# RockChip_RK3588 register map
Vendor: RockChip Electronics Co., Ltd.; Series: RK3588; File version: 0.1
Registers are 32-bit, read-write, no defined reset value unless marked. A register's access mark holds for its fields unless they carry their own. Offsets are from the block's base; [hi:lo] are bit positions; {n}, {i} and the like mark numbered series; 'fields as' and 'values as' point back to an identical list.

## CRU (part 2 of 6)
Base 0xFD7C0000
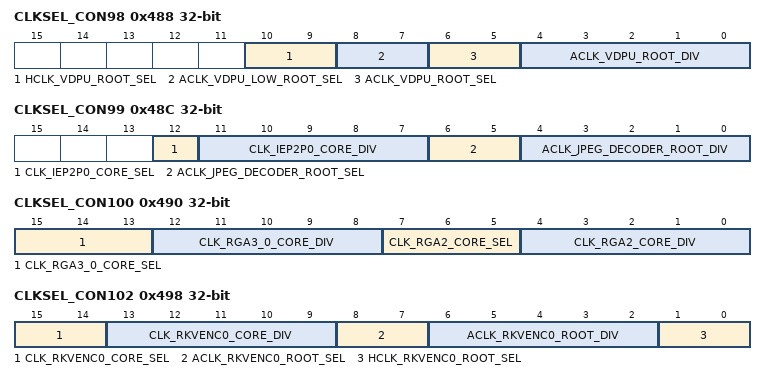
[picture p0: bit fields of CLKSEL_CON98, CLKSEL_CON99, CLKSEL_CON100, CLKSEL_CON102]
0x488 CLKSEL_CON98 — Internal clock select and division register 98
  [10:9] HCLK_VDPU_ROOT_SEL — hclk_vdpu_root clock mux.
    0=CLK_MATRIX_200M_SRC; 1=CLK_MATRIX_100M_SRC; 2=CLK_MATRIX_50M_SRC; 3=XIN_OSC0_FUNC
  [8:7] ACLK_VDPU_LOW_ROOT_SEL — aclk_vdpu_low_root clock mux.
    0=CLK_MATRIX_400M_SRC; 1=CLK_MATRIX_200M_SRC; 2=CLK_MATRIX_100M_SRC; 3=XIN_OSC0_FUNC
  [6:5] ACLK_VDPU_ROOT_SEL — aclk_vdpu_root clock mux.
    0=CLK_GPLL_MUX; 1=CLK_CPLL_MUX; 2=CLK_AUPLL_MUX
  [4:0] ACLK_VDPU_ROOT_DIV — Divide aclk_vdpu_root by (div_con + 1).
0x48C CLKSEL_CON99 — Internal clock select and division register 99
  [12] CLK_IEP2P0_CORE_SEL — clk_iep2p0_core clock mux.
    0=CLK_GPLL_MUX; 1=CLK_CPLL_MUX
  [11:7] CLK_IEP2P0_CORE_DIV — Divide clk_iep2p0_core by (div_con + 1).
  [6:5] ACLK_JPEG_DECODER_ROOT_SEL — aclk_jpeg_decoder_root clock mux.
    0=CLK_GPLL_MUX; 1=CLK_CPLL_MUX; 2=CLK_AUPLL_MUX; 3=CLK_SPLL_MUX
  [4:0] ACLK_JPEG_DECODER_ROOT_DIV — Divide aclk_jpeg_decoder_root by (div_con + 1).
0x490 CLKSEL_CON100 — Internal clock select and division register 100
  [15:13] CLK_RGA3_0_CORE_SEL — clk_rga3_0_core clock mux.
    0=CLK_GPLL_MUX; 1=CLK_CPLL_MUX; 2=CLK_NPLL_MUX; 3=CLK_AUPLL_MUX; 4=CLK_SPLL_MUX
  [12:8] CLK_RGA3_0_CORE_DIV — Divide clk_rga3_0_core by (div_con + 1).
  [7:5] CLK_RGA2_CORE_SEL — clk_rga2_core clock mux.
    values as CLK_RGA3_0_CORE_SEL
  [4:0] CLK_RGA2_CORE_DIV — Divide clk_rga2_core by (div_con + 1).
0x498 CLKSEL_CON102 — Internal clock select and division register 102
  [15:14] CLK_RKVENC0_CORE_SEL — clk_rkvenc0_core clock mux.
    0=CLK_GPLL_MUX; 1=CLK_CPLL_MUX; 2=CLK_AUPLL_MUX; 3=CLK_NPLL_MUX
  [13:9] CLK_RKVENC0_CORE_DIV — Divide clk_rkvenc0_core by (div_con + 1).
  [8:7] ACLK_RKVENC0_ROOT_SEL — aclk_rkvenc0_root clock mux.
    0=CLK_GPLL_MUX; 1=CLK_CPLL_MUX; 2=CLK_NPLL_MUX
  [6:2] ACLK_RKVENC0_ROOT_DIV — Divide aclk_rkvenc0_root by (div_con + 1).
  [1:0] HCLK_RKVENC0_ROOT_SEL — hclk_rkvenc0_root clock mux.
    values as CLKSEL_CON98.HCLK_VDPU_ROOT_SEL
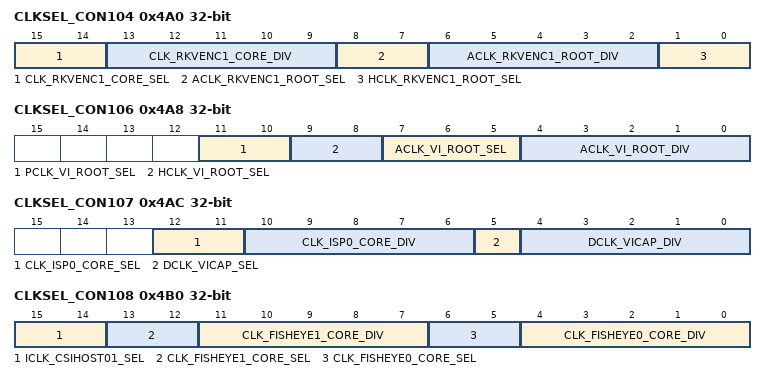
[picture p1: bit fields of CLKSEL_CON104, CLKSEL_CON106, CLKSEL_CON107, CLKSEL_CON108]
0x4A0 CLKSEL_CON104 — Internal clock select and division register 104
  [15:14] CLK_RKVENC1_CORE_SEL — clk_rkvenc1_core clock mux.
    values as CLKSEL_CON102.CLK_RKVENC0_CORE_SEL
  [13:9] CLK_RKVENC1_CORE_DIV — Divide clk_rkvenc1_core by (div_con + 1).
  [8:7] ACLK_RKVENC1_ROOT_SEL — aclk_rkvenc1_root clock mux.
    0=CLK_GPLL_MUX; 1=CLK_CPLL_MUX; 2=CLK_NPLL_MUX
  [6:2] ACLK_RKVENC1_ROOT_DIV — Divide aclk_rkvenc1_root by (div_con + 1).
  [1:0] HCLK_RKVENC1_ROOT_SEL — hclk_rkvenc1_root clock mux.
    values as CLKSEL_CON98.HCLK_VDPU_ROOT_SEL
0x4A8 CLKSEL_CON106 — Internal clock select and division register 106
  [11:10] PCLK_VI_ROOT_SEL — pclk_vi_root clock mux.
    0=CLK_MATRIX_100M_SRC; 1=CLK_MATRIX_50M_SRC; 2=XIN_OSC0_FUNC
  [9:8] HCLK_VI_ROOT_SEL — hclk_vi_root clock mux.
    values as CLKSEL_CON98.HCLK_VDPU_ROOT_SEL
  [7:5] ACLK_VI_ROOT_SEL — aclk_vi_root clock mux.
    values as CLKSEL_CON100.CLK_RGA3_0_CORE_SEL
  [4:0] ACLK_VI_ROOT_DIV — Divide aclk_vi_root by (div_con + 1).
0x4AC CLKSEL_CON107 — Internal clock select and division register 107
  [12:11] CLK_ISP0_CORE_SEL — clk_isp0_core clock mux.
    values as CLKSEL_CON99.ACLK_JPEG_DECODER_ROOT_SEL
  [10:6] CLK_ISP0_CORE_DIV — Divide clk_isp0_core by (div_con + 1).
  [5] DCLK_VICAP_SEL — dclk_vicap clock mux.
    0=CLK_GPLL_MUX; 1=CLK_CPLL_MUX
  [4:0] DCLK_VICAP_DIV — Divide dclk_vicap by (div_con + 1).
0x4B0 CLKSEL_CON108 — Internal clock select and division register 108
  [15:14] ICLK_CSIHOST01_SEL — iclk_csihost01 clock mux.
    values as CLKSEL_CON98.ACLK_VDPU_LOW_ROOT_SEL
  [13:12] CLK_FISHEYE1_CORE_SEL — clk_fisheye1_core clock mux.
    values as CLKSEL_CON99.ACLK_JPEG_DECODER_ROOT_SEL
  [11:7] CLK_FISHEYE1_CORE_DIV — Divide clk_fisheye1_core by (div_con + 1).
  [6:5] CLK_FISHEYE0_CORE_SEL — clk_fisheye0_core clock mux.
    values as CLKSEL_CON99.ACLK_JPEG_DECODER_ROOT_SEL
  [4:0] CLK_FISHEYE0_CORE_DIV — Divide clk_fisheye0_core by (div_con + 1).
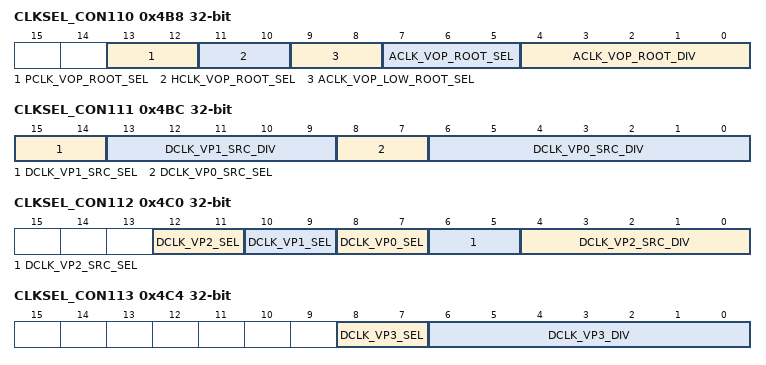
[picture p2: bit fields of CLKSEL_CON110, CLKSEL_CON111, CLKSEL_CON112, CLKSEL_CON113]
0x4B8 CLKSEL_CON110 — Internal clock select and division register 110
  [13:12] PCLK_VOP_ROOT_SEL — pclk_vop_root clock mux.
    0=CLK_MATRIX_100M_SRC; 1=CLK_MATRIX_50M_SRC; 2=XIN_OSC0_FUNC
  [11:10] HCLK_VOP_ROOT_SEL — hclk_vop_root clock mux.
    values as CLKSEL_CON98.HCLK_VDPU_ROOT_SEL
  [9:8] ACLK_VOP_LOW_ROOT_SEL — aclk_vop_low_root clock mux.
    values as CLKSEL_CON98.ACLK_VDPU_LOW_ROOT_SEL
  [7:5] ACLK_VOP_ROOT_SEL — aclk_vop_root clock mux.
    0=CLK_GPLL_MUX; 1=CLK_CPLL_MUX; 2=CLK_AUPLL_MUX; 3=CLK_NPLL_MUX; 4=CLK_SPLL_MUX
  [4:0] ACLK_VOP_ROOT_DIV — Divide aclk_vop_root by (div_con + 1).
0x4BC CLKSEL_CON111 — Internal clock select and division register 111
  [15:14] DCLK_VP1_SRC_SEL — dclk_vp1_src clock mux.
    0=CLK_GPLL_MUX; 1=CLK_CPLL_MUX; 2=CLK_V0PLL_MUX; 3=CLK_AUPLL_MUX
  [13:9] DCLK_VP1_SRC_DIV — Divide dclk_vp1_src by (div_con + 1).
  [8:7] DCLK_VP0_SRC_SEL — dclk_vp0_src clock mux.
    values as DCLK_VP1_SRC_SEL
  [6:0] DCLK_VP0_SRC_DIV — Divide dclk_vp0_src by (div_con + 1).
0x4C0 CLKSEL_CON112 — Internal clock select and division register 112
  [12:11] DCLK_VP2_SEL — dclk_vp2 clock mux.
    0=DCLK_VP2_SRC; 1=CLK_HDMIPHY_PIXEL0_O; 2=CLK_HDMIPHY_PIXEL1_O
  [10:9] DCLK_VP1_SEL — dclk_vp1 clock mux.
    0=DCLK_VP1_SRC; 1=CLK_HDMIPHY_PIXEL0_O; 2=CLK_HDMIPHY_PIXEL1_O
  [8:7] DCLK_VP0_SEL — dclk_vp0 clock mux.
    0=DCLK_VP0_SRC; 1=CLK_HDMIPHY_PIXEL0_O; 2=CLK_HDMIPHY_PIXEL1_O
  [6:5] DCLK_VP2_SRC_SEL — dclk_vp2_src clock mux.
    values as CLKSEL_CON111.DCLK_VP1_SRC_SEL
  [4:0] DCLK_VP2_SRC_DIV — Divide dclk_vop2_src by (div_con + 1).
0x4C4 CLKSEL_CON113 — Internal clock select and division register 113
  [8:7] DCLK_VP3_SEL — dclk_vp3 clock mux.
    values as CLKSEL_CON111.DCLK_VP1_SRC_SEL
  [6:0] DCLK_VP3_DIV — Divide dclk_vp3 by (div_con + 1).
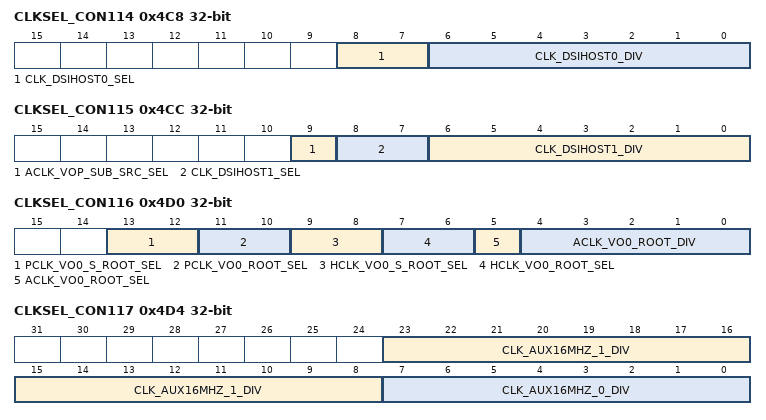
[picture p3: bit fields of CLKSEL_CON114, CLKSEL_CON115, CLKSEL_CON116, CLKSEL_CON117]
0x4C8 CLKSEL_CON114 — Internal clock select and division register 114
  [8:7] CLK_DSIHOST0_SEL — clk_dsihost0 clock mux.
    0=CLK_GPLL_MUX; 1=CLK_CPLL_MUX; 2=CLK_V0PLL_MUX; 3=CLK_SPLL_MUX
  [6:0] CLK_DSIHOST0_DIV — Divide clk_dsihost0 by (div_con + 1).
0x4CC CLKSEL_CON115 — Internal clock select and division register 115
  [9] ACLK_VOP_SUB_SRC_SEL — aclk_vop_sub_src clock mux.
    0=ACLK_VOP_ROOT; 1=ACLK_VOP_DIV2_SRC
  [8:7] CLK_DSIHOST1_SEL — clk_dsihost1 clock mux.
    values as CLKSEL_CON114.CLK_DSIHOST0_SEL
  [6:0] CLK_DSIHOST1_DIV — Divide clk_dsihost1 by (div_con + 1).
0x4D0 CLKSEL_CON116 — Internal clock select and division register 116
  [13:12] PCLK_VO0_S_ROOT_SEL — pclk_vo0_s_root clock mux.
    0=CLK_MATRIX_100M_SRC; 1=CLK_MATRIX_50M_SRC; 2=XIN_OSC0_FUNC
  [11:10] PCLK_VO0_ROOT_SEL — pclk_vo0_root clock mux.
    0=CLK_MATRIX_100M_SRC; 1=CLK_MATRIX_50M_SRC; 2=XIN_OSC0_FUNC
  [9:8] HCLK_VO0_S_ROOT_SEL — hclk_vo0_s_root clock mux.
    values as CLKSEL_CON98.HCLK_VDPU_ROOT_SEL
  [7:6] HCLK_VO0_ROOT_SEL — hclk_vo0_root clock mux.
    values as CLKSEL_CON98.HCLK_VDPU_ROOT_SEL
  [5] ACLK_VO0_ROOT_SEL — aclk_vo0_root clock mux.
    0=CLK_GPLL_MUX; 1=CLK_CPLL_MUX
  [4:0] ACLK_VO0_ROOT_DIV — Divide aclk_vo0_root by (div_con + 1).
0x4D4 CLKSEL_CON117 — Internal clock select and division register 117
  [23:8] CLK_AUX16MHZ_1_DIV — Divide clk_aux16mhz_1 by (div_con + 1).
  [7:0] CLK_AUX16MHZ_0_DIV — Divide clk_aux16mhz_0 by (div_con + 1).
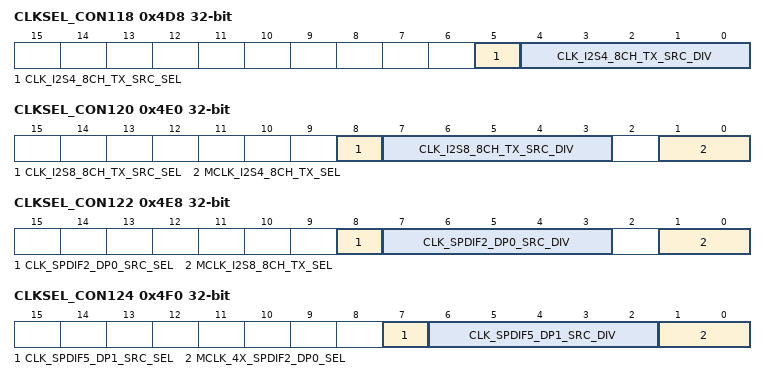
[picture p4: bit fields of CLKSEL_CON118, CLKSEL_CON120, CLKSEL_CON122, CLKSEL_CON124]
0x4D8 CLKSEL_CON118 — Internal clock select and division register 118
  [5] CLK_I2S4_8CH_TX_SRC_SEL — clk_i2s4_8ch_tx_src clock mux.
    0=CLK_GPLL_MUX; 1=CLK_AUPLL_MUX
  [4:0] CLK_I2S4_8CH_TX_SRC_DIV — Divide clk_i2s4_8ch_tx_src by (div_con + 1).
0x4DC CLKSEL_CON119 — Internal clock select and division register 119
  [31:0] CLK_I2S4_8CH_TX_FRAC_DIV — clk_i2s4_8ch_tx_frac fraction division register. High 16-bit for numerator Low 16-bit for denominator
0x4E0 CLKSEL_CON120 — Internal clock select and division register 120
  [8] CLK_I2S8_8CH_TX_SRC_SEL — clk_i2s8_8ch_tx_src clock mux.
    0=CLK_GPLL_MUX; 1=CLK_AUPLL_MUX
  [7:3] CLK_I2S8_8CH_TX_SRC_DIV — Divide clk_i2s8_8ch_tx_src by (div_con + 1).
  [1:0] MCLK_I2S4_8CH_TX_SEL — mclk_i2s4_8ch_tx clock mux.
    0=CLK_I2S4_8CH_TX_SRC; 1=CLK_I2S4_8CH_TX_FRAC; 2=I2S4_MCLKIN; 3=XIN_OSC0_HALF
0x4E4 CLKSEL_CON121 — Internal clock select and division register 121
  [31:0] CLK_I2S8_8CH_TX_FRAC_DIV — clk_i2s8_8ch_tx_frac fraction division register. High 16-bit for numerator Low 16-bit for denominator
0x4E8 CLKSEL_CON122 — Internal clock select and division register 122
  [8] CLK_SPDIF2_DP0_SRC_SEL — clk_spdif2_dp0_src clock mux.
    0=CLK_GPLL_MUX; 1=CLK_AUPLL_MUX
  [7:3] CLK_SPDIF2_DP0_SRC_DIV — Divide clk_spdif2_dp0_src by (div_con + 1).
  [1:0] MCLK_I2S8_8CH_TX_SEL — mclk_i2s8_8ch_tx clock mux.
    0=CLK_I2S8_8CH_TX_SRC; 1=CLK_I2S8_8CH_TX_FRAC; 2=I2S8_MCLKIN; 3=XIN_OSC0_HALF
0x4EC CLKSEL_CON123 — Internal clock select and division register 123
  [31:0] CLK_SPDIF2_DP0_FRAC_DIV — clk_spdif2_dp0_frac fraction division register. High 16-bit for numerator Low 16-bit for denominator
0x4F0 CLKSEL_CON124 — Internal clock select and division register 124
  [7] CLK_SPDIF5_DP1_SRC_SEL — clk_spdif5_dp1_src clock mux.
    0=CLK_GPLL_MUX; 1=CLK_AUPLL_MUX
  [6:2] CLK_SPDIF5_DP1_SRC_DIV — Divide clk_spdif5_dp1_src by (div_con + 1).
  [1:0] MCLK_4X_SPDIF2_DP0_SEL — mclk_4x_spdif2_dp0 clock mux.
    0=CLK_SPDIF2_DP0_SRC; 1=CLK_SPDIF2_DP0_FRAC; 2=XIN_OSC0_HALF
0x4F4 CLKSEL_CON125 — Internal clock select and division register 125
  [31:0] CLK_SPDIF5_DP1_FRAC_DIV — clk_spdif5_dp1_frac fraction division register. High 16-bit for numerator Low 16-bit for denominator
0x4F8 CLKSEL_CON126 — Internal clock select and division register 126
  [1:0] MCLK_4X_SPDIF5_DP1_SEL — mclk_4x_spdif5_dp1 clock mux.
    0=CLK_SPDIF5_DP1_SRC; 1=CLK_SPDIF5_DP1_FRAC; 2=XIN_OSC0_HALF
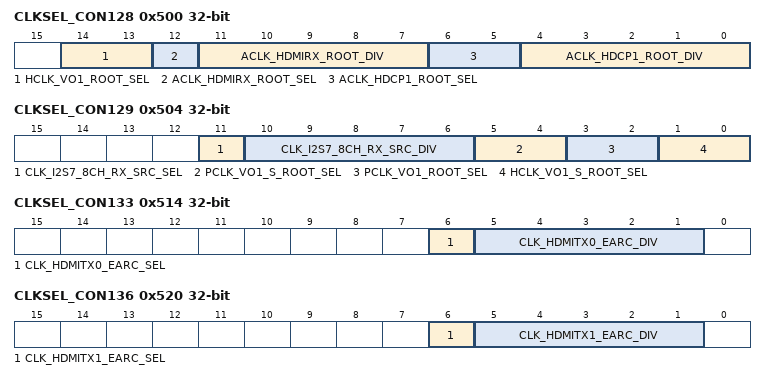
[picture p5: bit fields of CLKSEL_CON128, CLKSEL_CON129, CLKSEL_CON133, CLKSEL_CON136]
0x500 CLKSEL_CON128 — Internal clock select and division register 128
  [14:13] HCLK_VO1_ROOT_SEL — hclk_vo1_root clock mux.
    values as CLKSEL_CON98.HCLK_VDPU_ROOT_SEL
  [12] ACLK_HDMIRX_ROOT_SEL — aclk_hdmirx_root clock mux.
    0=CLK_GPLL_MUX; 1=CLK_CPLL_MUX
  [11:7] ACLK_HDMIRX_ROOT_DIV — Divide aclk_hdmirx_root by (div_con + 1).
  [6:5] ACLK_HDCP1_ROOT_SEL — aclk_hdcp1_root clock mux.
    0=CLK_GPLL_MUX; 1=CLK_CPLL_MUX; 2=CLK_HDMITRX_REFSRC
  [4:0] ACLK_HDCP1_ROOT_DIV — Divide aclk_hdcp1_root by (div_con + 1).
0x504 CLKSEL_CON129 — Internal clock select and division register 129
  [11] CLK_I2S7_8CH_RX_SRC_SEL — clk_i2s7_8ch_rx_src clock mux.
    0=CLK_GPLL_MUX; 1=CLK_AUPLL_MUX
  [10:6] CLK_I2S7_8CH_RX_SRC_DIV — Divide clk_i2s7_8ch_rx_src by (div_con + 1).
  [5:4] PCLK_VO1_S_ROOT_SEL — pclk_vo1_s_root clock mux.
    0=CLK_MATRIX_100M_SRC; 1=CLK_MATRIX_50M_SRC; 2=XIN_OSC0_FUNC
  [3:2] PCLK_VO1_ROOT_SEL — pclk_vo1_root clock mux.
    0=CLK_MATRIX_150M_SRC; 1=CLK_MATRIX_100M_SRC; 2=XIN_OSC0_FUNC
  [1:0] HCLK_VO1_S_ROOT_SEL — hclk_vo1_s_root clock mux.
    values as CLKSEL_CON98.HCLK_VDPU_ROOT_SEL
0x508 CLKSEL_CON130 — Internal clock select and division register 130
  [31:0] CLK_I2S7_8CH_RX_FRAC_DIV — clk_i2s7_8ch_rx_frac fraction division register. High 16-bit for numerator Low 16-bit for denominator
0x50C CLKSEL_CON131 — Internal clock select and division register 131
  [1:0] MCLK_I2S7_8CH_RX_SEL — mclk_i2s7_8ch_rx clock mux.
    0=CLK_I2S7_8CH_RX_SRC; 1=CLK_I2S7_8CH_RX_FRAC; 2=I2S7_MCLKIN; 3=XIN_OSC0_HALF
0x514 CLKSEL_CON133 — Internal clock select and division register 133
  [6] CLK_HDMITX0_EARC_SEL — clk_hdmitx0_earc clock mux.
    0=CLK_GPLL_MUX; 1=CLK_CPLL_MUX
  [5:1] CLK_HDMITX0_EARC_DIV — Divide clk_hdmitx0_earc by (div_con + 1).
0x520 CLKSEL_CON136 — Internal clock select and division register 136
  [6] CLK_HDMITX1_EARC_SEL — clk_hdmitx1_earc clock mux.
    0=CLK_GPLL_MUX; 1=CLK_CPLL_MUX
  [5:1] CLK_HDMITX1_EARC_DIV — Divide clk_hdmitx1_earc by (div_con + 1).
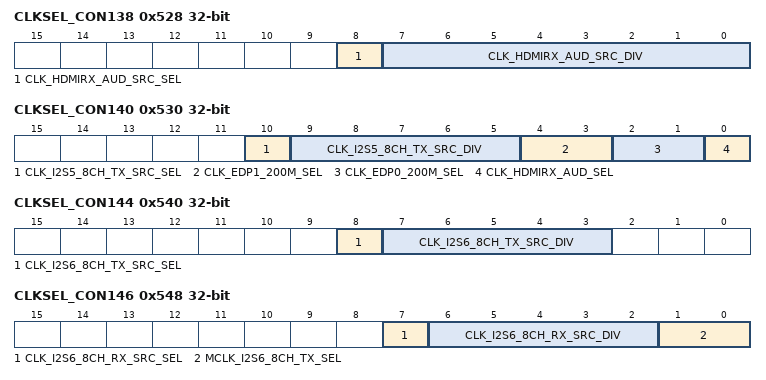
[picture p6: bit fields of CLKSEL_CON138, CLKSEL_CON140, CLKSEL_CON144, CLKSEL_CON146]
0x528 CLKSEL_CON138 — Internal clock select and division register 138
  [8] CLK_HDMIRX_AUD_SRC_SEL — clk_hdmirx_aud_src clock mux.
    0=CLK_GPLL_MUX; 1=CLK_AUPLL_MUX
  [7:0] CLK_HDMIRX_AUD_SRC_DIV — Divide clk_hdmirx_aud_src by (div_con + 1).
0x52C CLKSEL_CON139 — Internal clock select and division register 139
  [31:0] CLK_HDMIRX_AUD_FRAC_DIV — clk_hdmirx_aud_frac fraction division register. High 16-bit for numerator Low 16-bit for denominator
0x530 CLKSEL_CON140 — Internal clock select and division register 140
  [10] CLK_I2S5_8CH_TX_SRC_SEL — clk_i2s5_8ch_tx_src clock mux.
    0=CLK_GPLL_MUX; 1=CLK_AUPLL_MUX
  [9:5] CLK_I2S5_8CH_TX_SRC_DIV — Divide clk_i2s5_8ch_tx_src by (div_con + 1).
  [4:3] CLK_EDP1_200M_SEL — clk_edp1_200m clock mux.
    values as CLKSEL_CON98.HCLK_VDPU_ROOT_SEL
  [2:1] CLK_EDP0_200M_SEL — clk_edp0_200m clock mux.
    values as CLKSEL_CON98.HCLK_VDPU_ROOT_SEL
  [0] CLK_HDMIRX_AUD_SEL — clk_hdmirx_aud clock mux.
    0=CLK_HDMIRX_AUD_SRC; 1=CLK_HDMIRX_AUD_FRAC
0x534 CLKSEL_CON141 — Internal clock select and division register 141
  [31:0] CLK_I2S5_8CH_TX_FRAC_DIV — clk_i2s5_8ch_tx_frac fraction division register. High 16-bit for numerator Low 16-bit for denominator
0x538 CLKSEL_CON142 — Internal clock select and division register 142
  [1:0] MCLK_I2S5_8CH_TX_SEL — mclk_i2s5_8ch_tx clock mux.
    0=CLK_I2S5_8CH_TX_SRC; 1=CLK_I2S5_8CH_TX_FRAC; 2=I2S5_MCLKIN; 3=XIN_OSC0_HALF
0x540 CLKSEL_CON144 — Internal clock select and division register 144
  [8] CLK_I2S6_8CH_TX_SRC_SEL — clk_i2s6_8ch_tx_src clock mux.
    0=CLK_GPLL_MUX; 1=CLK_AUPLL_MUX
  [7:3] CLK_I2S6_8CH_TX_SRC_DIV — Divide clk_i2s6_8ch_tx_src by (div_con + 1).
0x544 CLKSEL_CON145 — Internal clock select and division register 145
  [31:0] CLK_I2S6_8CH_TX_FRAC_DIV — clk_i2s6_8ch_tx_frac fraction division register. High 16-bit for numerator Low 16-bit for denominator
0x548 CLKSEL_CON146 — Internal clock select and division register 146
  [7] CLK_I2S6_8CH_RX_SRC_SEL — clk_i2s6_8ch_rx_src clock mux.
    0=CLK_GPLL_MUX; 1=CLK_AUPLL_MUX
  [6:2] CLK_I2S6_8CH_RX_SRC_DIV — Divide clk_i2s6_8ch_rx_src by (div_con + 1).
  [1:0] MCLK_I2S6_8CH_TX_SEL — mclk_i2s6_8ch_tx clock mux.
    0=CLK_I2S6_8CH_TX_SRC; 1=CLK_I2S6_8CH_TX_FRAC; 2=I2S6_MCLKIN; 3=XIN_OSC0_HALF
0x54C CLKSEL_CON147 — Internal clock select and division register 147
  [31:0] CLK_I2S6_8CH_RX_FRAC_DIV — clk_i2s6_8ch_rx_frac fraction division register. High 16-bit for numerator Low 16-bit for denominator
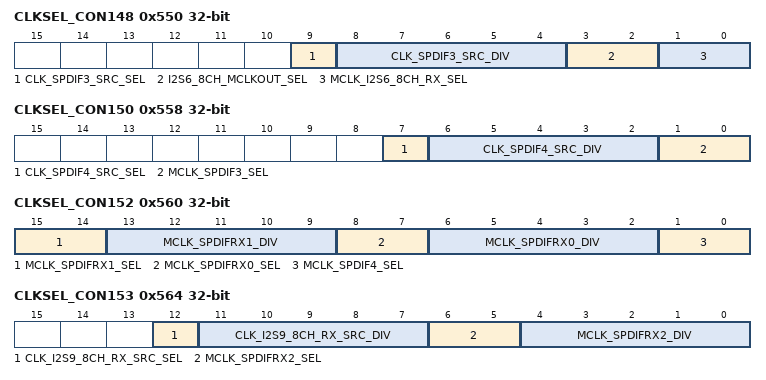
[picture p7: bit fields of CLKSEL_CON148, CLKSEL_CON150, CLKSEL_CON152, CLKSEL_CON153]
0x550 CLKSEL_CON148 — Internal clock select and division register 148
  [9] CLK_SPDIF3_SRC_SEL — clk_spdif3_src clock mux.
    0=CLK_GPLL_MUX; 1=CLK_AUPLL_MUX
  [8:4] CLK_SPDIF3_SRC_DIV — Divide clk_spdif3_src by (div_con + 1).
  [3:2] I2S6_8CH_MCLKOUT_SEL — i2s6_8ch_mclkout clock mux.
    0=MCLK_I2S6_8CH_TX; 1=MCLK_I2S6_8CH_RX; 2=XIN_OSC0_HALF
  [1:0] MCLK_I2S6_8CH_RX_SEL — mclk_i2s6_8ch_rx clock mux.
    0=CLK_I2S6_8CH_RX_SRC; 1=CLK_I2S6_8CH_RX_FRAC; 2=I2S6_MCLKIN; 3=XIN_OSC0_HALF
0x554 CLKSEL_CON149 — Internal clock select and division register 149
  [31:0] CLK_SPDIF3_FRAC_DIV — clk_spdif3_frac fraction division register. High 16-bit for numerator Low 16-bit for denominator
0x558 CLKSEL_CON150 — Internal clock select and division register 150
  [7] CLK_SPDIF4_SRC_SEL — clk_spdif4_src clock mux.
    0=CLK_GPLL_MUX; 1=CLK_AUPLL_MUX
  [6:2] CLK_SPDIF4_SRC_DIV — Divide clk_spdif4_src by (div_con + 1).
  [1:0] MCLK_SPDIF3_SEL — mclk_spdif3 clock mux.
    0=CLK_SPDIF3_SRC; 1=CLK_SPDIF3_FRAC; 2=XIN_OSC0_HALF
0x55C CLKSEL_CON151 — Internal clock select and division register 151
  [31:0] CLK_SPDIF4_FRAC_DIV — clk_spdif4_frac fraction division register. High 16-bit for numerator Low 16-bit for denominator
0x560 CLKSEL_CON152 — Internal clock select and division register 152
  [15:14] MCLK_SPDIFRX1_SEL — mclk_spdifrx1 clock mux.
    0=CLK_GPLL_MUX; 1=CLK_CPLL_MUX; 2=CLK_AUPLL_MUX
  [13:9] MCLK_SPDIFRX1_DIV — Divide mclk_spdifrx1 by (div_con + 1).
  [8:7] MCLK_SPDIFRX0_SEL — mclk_spdifrx0 clock mux.
    0=CLK_GPLL_MUX; 1=CLK_CPLL_MUX; 2=CLK_AUPLL_MUX
  [6:2] MCLK_SPDIFRX0_DIV — Divide mclk_spdifrx0 by (div_con + 1).
  [1:0] MCLK_SPDIF4_SEL — mclk_spdif4 clock mux.
    0=CLK_SPDIF4_SRC; 1=CLK_SPDIF4_FRAC; 2=XIN_OSC0_HALF
0x564 CLKSEL_CON153 — Internal clock select and division register 153
  [12] CLK_I2S9_8CH_RX_SRC_SEL — clk_i2s9_8ch_rx_src clock mux.
    0=CLK_GPLL_MUX; 1=CLK_AUPLL_MUX
  [11:7] CLK_I2S9_8CH_RX_SRC_DIV — Divide clk_i2s9_8ch_rx_src by (div_con + 1).
  [6:5] MCLK_SPDIFRX2_SEL — mclk_spdifrx2 clock mux.
    0=CLK_GPLL_MUX; 1=CLK_CPLL_MUX; 2=CLK_AUPLL_MUX
  [4:0] MCLK_SPDIFRX2_DIV — Divide mclk_spdifrx2 by (div_con + 1).
0x568 CLKSEL_CON154 — Internal clock select and division register 154
  [31:0] CLK_I2S9_8CH_RX_FRAC_DIV — clk_i2s9_8ch_rx_frac fraction division register. High 16-bit for numerator Low 16-bit for denominator
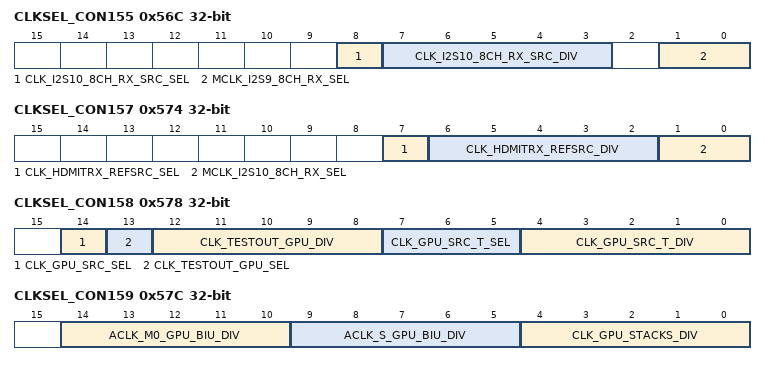
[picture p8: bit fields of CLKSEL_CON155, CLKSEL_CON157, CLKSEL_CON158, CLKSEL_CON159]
0x56C CLKSEL_CON155 — Internal clock select and division register 155
  [8] CLK_I2S10_8CH_RX_SRC_SEL — clk_i2s10_8ch_rx_src clock mux.
    0=CLK_GPLL_MUX; 1=CLK_AUPLL_MUX
  [7:3] CLK_I2S10_8CH_RX_SRC_DIV — Divide clk_i2s10_8ch_rx_src by (div_con + 1).
  [1:0] MCLK_I2S9_8CH_RX_SEL — mclk_i2s9_8ch_rx clock mux.
    0=CLK_I2S9_8CH_RX_SRC; 1=CLK_I2S9_8CH_RX_FRAC; 2=I2S9_MCLKIN; 3=XIN_OSC0_HALF
0x570 CLKSEL_CON156 — Internal clock select and division register 156
  [31:0] CLK_I2S10_8CH_RX_FRAC_DIV — clk_i2s10_8ch_rx_frac fraction division register. High 16-bit for numerator Low 16-bit for denominator
0x574 CLKSEL_CON157 — Internal clock select and division register 157
  [7] CLK_HDMITRX_REFSRC_SEL — clk_hdmitrx_refsrc clock mux.
    0=CLK_GPLL_MUX; 1=CLK_CPLL_MUX
  [6:2] CLK_HDMITRX_REFSRC_DIV — NP5 division register. Divide clk_hdmitrx_refsrc by ((2 * div_con + 3) / 2).
  [1:0] MCLK_I2S10_8CH_RX_SEL — mclk_i2s10_8ch_rx clock mux.
    0=CLK_I2S10_8CH_RX_SRC; 1=CLK_I2S10_8CH_RX_FRAC; 2=I2S10_MCLKIN; 3=XIN_OSC0_HALF
0x578 CLKSEL_CON158 — Internal clock select and division register 158
  [14] CLK_GPU_SRC_SEL — clk_gpu_src clock mux.
    0=CLK_GPU_SRC_T; 1=CLK_GPU_PVTPLL
  [13] CLK_TESTOUT_GPU_SEL — clk_testout_gpu clock mux.
    0=CLK_GPU_SRC_T; 1=CLK_GPU_PVTPLL
  [12:8] CLK_TESTOUT_GPU_DIV — Divide clk_testout_gpu by (div_con + 1).
  [7:5] CLK_GPU_SRC_T_SEL — clk_gpu_src_t clock mux.
    values as CLKSEL_CON110.ACLK_VOP_ROOT_SEL
  [4:0] CLK_GPU_SRC_T_DIV — Divide clk_gpu_src_t by (div_con + 1).
0x57C CLKSEL_CON159 — Internal clock select and division register 159
  [14:10] ACLK_M0_GPU_BIU_DIV — Divide aclk_m0_gpu_biu by (div_con + 1).
  [9:5] ACLK_S_GPU_BIU_DIV — Divide aclk_s_gpu_biu by (div_con + 1).
  [4:0] CLK_GPU_STACKS_DIV — Divide clk_gpu_stacks by (div_con + 1).
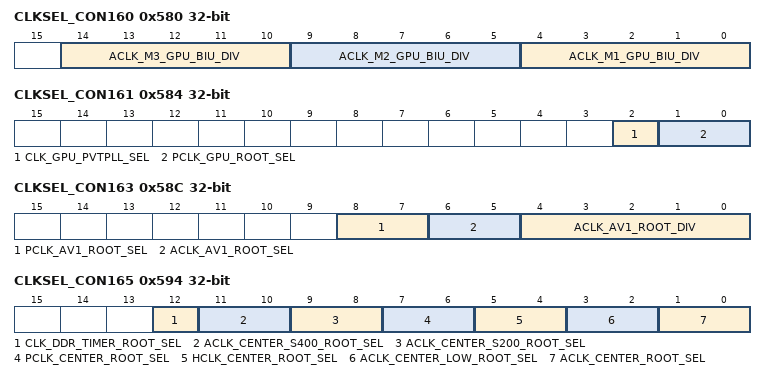
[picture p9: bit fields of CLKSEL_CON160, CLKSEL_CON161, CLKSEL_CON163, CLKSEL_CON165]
0x580 CLKSEL_CON160 — Internal clock select and division register 160
  [14:10] ACLK_M3_GPU_BIU_DIV — Divide aclk_m3_gpu_biu by (div_con + 1).
  [9:5] ACLK_M2_GPU_BIU_DIV — Divide aclk_m2_gpu_biu by (div_con + 1).
  [4:0] ACLK_M1_GPU_BIU_DIV — Divide aclk_m1_gpu_biu by (div_con + 1).
0x584 CLKSEL_CON161 — Internal clock select and division register 161
  [2] CLK_GPU_PVTPLL_SEL — clk_gpu_pvtpll clock mux.
    0=CLK_GPU_SRC_T; 1=XIN_OSC0_FUNC
  [1:0] PCLK_GPU_ROOT_SEL — pclk_gpu_root clock mux.
    0=CLK_MATRIX_100M_SRC; 1=CLK_MATRIX_50M_SRC; 2=XIN_OSC0_FUNC
0x58C CLKSEL_CON163 — Internal clock select and division register 163
  [8:7] PCLK_AV1_ROOT_SEL — pclk_av1_root clock mux.
    values as CLKSEL_CON98.HCLK_VDPU_ROOT_SEL
  [6:5] ACLK_AV1_ROOT_SEL — aclk_av1_root clock mux.
    0=CLK_GPLL_MUX; 1=CLK_CPLL_MUX; 2=CLK_AUPLL_MUX
  [4:0] ACLK_AV1_ROOT_DIV — Divide aclk_av1_root by (div_con + 1).
0x594 CLKSEL_CON165 — Internal clock select and division register 165
  [12] CLK_DDR_TIMER_ROOT_SEL — clk_ddr_timer_root clock mux.
    0=XIN_OSC0_FUNC; 1=CLK_MATRIX_100M_SRC
  [11:10] ACLK_CENTER_S400_ROOT_SEL — aclk_center_s400_root clock mux.
    values as CLKSEL_CON98.ACLK_VDPU_LOW_ROOT_SEL
  [9:8] ACLK_CENTER_S200_ROOT_SEL — aclk_center_s200_root clock mux.
    values as CLKSEL_CON98.HCLK_VDPU_ROOT_SEL
  [7:6] PCLK_CENTER_ROOT_SEL — pclk_center_root clock mux.
    values as CLKSEL_CON98.HCLK_VDPU_ROOT_SEL
  [5:4] HCLK_CENTER_ROOT_SEL — hclk_center_root clock mux.
    values as CLKSEL_CON98.ACLK_VDPU_LOW_ROOT_SEL
  [3:2] ACLK_CENTER_LOW_ROOT_SEL — aclk_center_low_root clock mux.
    0=CLK_MATRIX_500M_SRC; 1=CLK_MATRIX_250M_SRC; 2=CLK_MATRIX_100M_SRC; 3=XIN_OSC0_FUNC
  [1:0] ACLK_CENTER_ROOT_SEL — aclk_center_root clock mux.
    0=CLK_MATRIX_700M_SRC; 1=CLK_MATRIX_400M_SRC; 2=CLK_MATRIX_200M_SRC; 3=XIN_OSC0_FUNC
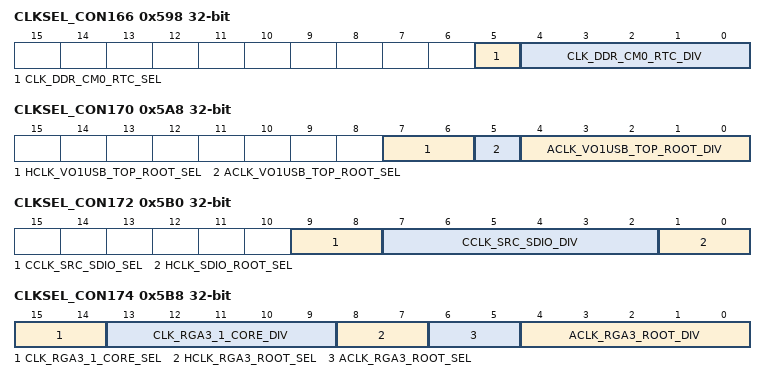
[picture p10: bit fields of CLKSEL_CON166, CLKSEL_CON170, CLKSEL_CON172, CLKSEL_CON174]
0x598 CLKSEL_CON166 — Internal clock select and division register 166
  [5] CLK_DDR_CM0_RTC_SEL — clk_ddr_cm0_rtc clock mux.
    0=XIN_OSC0_FUNC; 1=CLK_DEEPSLOW
  [4:0] CLK_DDR_CM0_RTC_DIV — Divide clk_ddr_cm0_rtc by (div_con + 1).
0x5A8 CLKSEL_CON170 — Internal clock select and division register 170
  [7:6] HCLK_VO1USB_TOP_ROOT_SEL — hclk_vo1usb_top_root clock mux.
    values as CLKSEL_CON98.HCLK_VDPU_ROOT_SEL
  [5] ACLK_VO1USB_TOP_ROOT_SEL — aclk_vo1usb_top_root clock mux.
    0=CLK_GPLL_MUX; 1=CLK_CPLL_MUX
  [4:0] ACLK_VO1USB_TOP_ROOT_DIV — Divide aclk_vo1usb_top_root by (div_con + 1).
0x5B0 CLKSEL_CON172 — Internal clock select and division register 172
  [9:8] CCLK_SRC_SDIO_SEL — cclk_src_sdio clock mux.
    0=CLK_GPLL_MUX; 1=CLK_CPLL_MUX; 2=XIN_OSC0_FUNC
  [7:2] CCLK_SRC_SDIO_DIV — DT50 division register. Divide cclk_src_sdio by (div_con + 1).
  [1:0] HCLK_SDIO_ROOT_SEL — hclk_sdio_root clock mux.
    values as CLKSEL_CON98.HCLK_VDPU_ROOT_SEL
0x5B8 CLKSEL_CON174 — Internal clock select and division register 174
  [15:14] CLK_RGA3_1_CORE_SEL — clk_rga3_1_core clock mux.
    values as CLKSEL_CON99.ACLK_JPEG_DECODER_ROOT_SEL
  [13:9] CLK_RGA3_1_CORE_DIV — Divide clk_rga3_1_core by (div_con + 1).
  [8:7] HCLK_RGA3_ROOT_SEL — hclk_rga3_root clock mux.
    values as CLKSEL_CON98.HCLK_VDPU_ROOT_SEL
  [6:5] ACLK_RGA3_ROOT_SEL — aclk_rga3_root clock mux.
    0=CLK_GPLL_MUX; 1=CLK_CPLL_MUX; 2=CLK_AUPLL_MUX
  [4:0] ACLK_RGA3_ROOT_DIV — Divide aclk_rga3_root by (div_con + 1).
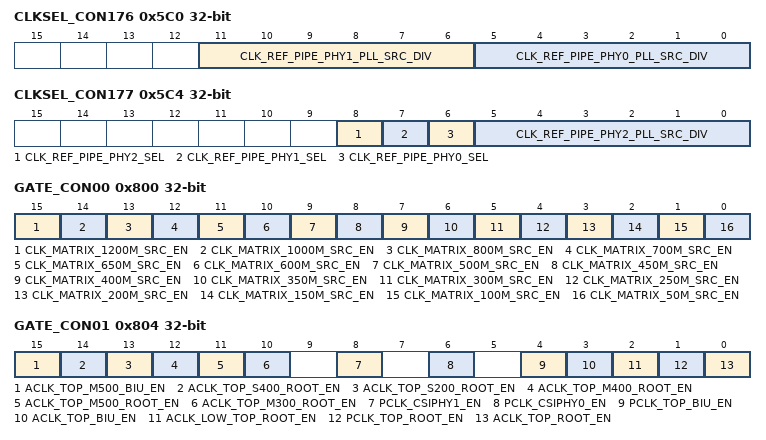
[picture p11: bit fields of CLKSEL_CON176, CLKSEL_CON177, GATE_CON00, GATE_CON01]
0x5C0 CLKSEL_CON176 — Internal clock select and division register 176
  [11:6] CLK_REF_PIPE_PHY1_PLL_SRC_DIV — Divide clk_ref_pipe_phy1_pll_src by (div_con + 1).
  [5:0] CLK_REF_PIPE_PHY0_PLL_SRC_DIV — Divide clk_ref_pipe_phy0_pll_src by (div_con + 1).
0x5C4 CLKSEL_CON177 — Internal clock select and division register 177
  [8] CLK_REF_PIPE_PHY2_SEL — clk_ref_pipe_phy2 clock mux.
    0=CLK_REF_PIPE_PHY2_OSC_SRC; 1=CLK_REF_PIPE_PHY2_PLL_SRC
  [7] CLK_REF_PIPE_PHY1_SEL — clk_ref_pipe_phy1 clock mux.
    0=CLK_REF_PIPE_PHY1_OSC_SRC; 1=CLK_REF_PIPE_PHY1_PLL_SRC
  [6] CLK_REF_PIPE_PHY0_SEL — clk_ref_pipe_phy0 clock mux.
    0=CLK_REF_PIPE_PHY0_OSC_SRC; 1=CLK_REF_PIPE_PHY0_PLL_SRC
  [5:0] CLK_REF_PIPE_PHY2_PLL_SRC_DIV — Divide clk_ref_pipe_phy2_pll_src by (div_con + 1).
0x800 GATE_CON00 — Internal clock gate and division register 0
  [all] fields
    1=DISABLE; 0=ENABLE
  [15] CLK_MATRIX_1200M_SRC_EN — clk_matrix_1200m_src clock gating control.
  [14] CLK_MATRIX_1000M_SRC_EN — clk_matrix_1000m_src clock gating control.
  [13] CLK_MATRIX_800M_SRC_EN — clk_matrix_800m_src clock gating control.
  [12] CLK_MATRIX_700M_SRC_EN — clk_matrix_700m_src clock gating control.
  [11] CLK_MATRIX_650M_SRC_EN — clk_matrix_650m_src clock gating control.
  [10] CLK_MATRIX_600M_SRC_EN — clk_matrix_600m_src clock gating control.
  [9] CLK_MATRIX_500M_SRC_EN — clk_matrix_500m_src clock gating control.
  [8] CLK_MATRIX_450M_SRC_EN — clk_matrix_450m_src clock gating control.
  [7] CLK_MATRIX_400M_SRC_EN — clk_matrix_400m_src clock gating control.
  [6] CLK_MATRIX_350M_SRC_EN — clk_matrix_350m_src clock gating control.
  [5] CLK_MATRIX_300M_SRC_EN — clk_matrix_300m_src clock gating control.
  [4] CLK_MATRIX_250M_SRC_EN — clk_matrix_250m_src clock gating control.
  [3] CLK_MATRIX_200M_SRC_EN — clk_matrix_200m_src clock gating control.
  [2] CLK_MATRIX_150M_SRC_EN — clk_matrix_150m_src clock gating control.
  [1] CLK_MATRIX_100M_SRC_EN — clk_matrix_100m_src clock gating control.
  [0] CLK_MATRIX_50M_SRC_EN — clk_matrix_50m_src clock gating control.
0x804 GATE_CON01 — Internal clock gate and division register 1
  [all] fields
    1=DISABLE; 0=ENABLE
  [15] ACLK_TOP_M500_BIU_EN — aclk_top_m500_biu clock gating control.
  [14] ACLK_TOP_S400_ROOT_EN — aclk_top_s400_root clock gating control.
  [13] ACLK_TOP_S200_ROOT_EN — aclk_top_s200_root clock gating control.
  [12] ACLK_TOP_M400_ROOT_EN — aclk_top_m400_root clock gating control.
  [11] ACLK_TOP_M500_ROOT_EN — aclk_top_m500_root clock gating control.
  [10] ACLK_TOP_M300_ROOT_EN — aclk_top_m300_root clock gating control.
  [8] PCLK_CSIPHY1_EN — pclk_csiphy1 clock gating control.
  [6] PCLK_CSIPHY0_EN — pclk_csiphy0 clock gating control.
  [4] PCLK_TOP_BIU_EN — pclk_top_biu clock gating control.
  [3] ACLK_TOP_BIU_EN — aclk_top_biu clock gating control.
  [2] ACLK_LOW_TOP_ROOT_EN — aclk_low_top_root clock gating control.
  [1] PCLK_TOP_ROOT_EN — pclk_top_root clock gating control.
  [0] ACLK_TOP_ROOT_EN — aclk_top_root clock gating control.
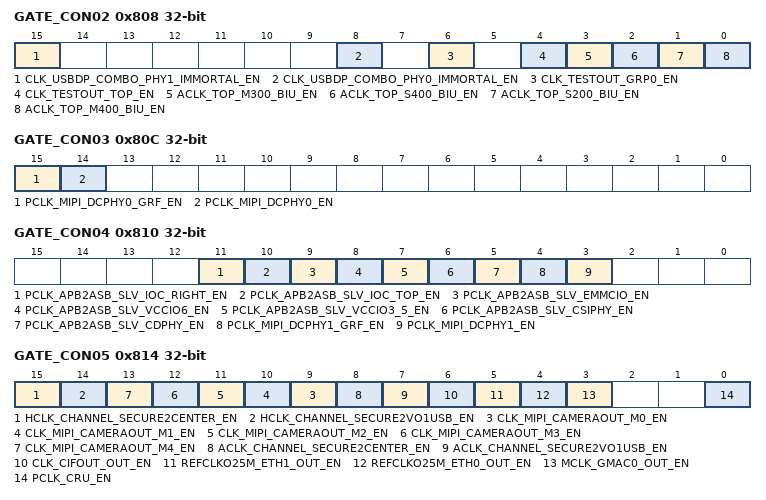
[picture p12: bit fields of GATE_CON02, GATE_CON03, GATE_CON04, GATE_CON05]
0x808 GATE_CON02 — Internal clock gate and division register 2
  [all] fields
    1=DISABLE; 0=ENABLE
  [15] CLK_USBDP_COMBO_PHY1_IMMORTAL_EN — clk_usbdp_combo_phy1_immortal clock gating control.
  [8] CLK_USBDP_COMBO_PHY0_IMMORTAL_EN — clk_usbdp_combo_phy0_immortal clock gating control.
  [6] CLK_TESTOUT_GRP0_EN — clk_testout_grp0 clock gating control.
  [4] CLK_TESTOUT_TOP_EN — clk_testout_top clock gating control.
  [3] ACLK_TOP_M300_BIU_EN — aclk_top_m300_biu clock gating control.
  [2] ACLK_TOP_S400_BIU_EN — aclk_top_s400_biu clock gating control.
  [1] ACLK_TOP_S200_BIU_EN — aclk_top_s200_biu clock gating control.
  [0] ACLK_TOP_M400_BIU_EN — aclk_top_m400_biu clock gating control.
0x80C GATE_CON03 — Internal clock gate and division register 3
  [15] PCLK_MIPI_DCPHY0_GRF_EN — pclk_mipi_dcphy0_grf clock gating control.
    1=DISABLE; 0=ENABLE
  [14] PCLK_MIPI_DCPHY0_EN — pclk_mipi_dcphy0 clock gating control.
    1=DISABLE; 0=ENABLE
0x810 GATE_CON04 — Internal clock gate and division register 4
  [all] fields
    1=DISABLE; 0=ENABLE
  [11] PCLK_APB2ASB_SLV_IOC_RIGHT_EN — pclk_apb2asb_slv_ioc_right clock gating control.
  [10] PCLK_APB2ASB_SLV_IOC_TOP_EN — pclk_apb2asb_slv_ioc_top clock gating control.
  [9] PCLK_APB2ASB_SLV_EMMCIO_EN — pclk_apb2asb_slv_emmcio clock gating control.
  [8] PCLK_APB2ASB_SLV_VCCIO6_EN — pclk_apb2asb_slv_vccio6 clock gating control.
  [7] PCLK_APB2ASB_SLV_VCCIO3_5_EN — pclk_apb2asb_slv_vccio3_5 clock gating control.
  [6] PCLK_APB2ASB_SLV_CSIPHY_EN — pclk_apb2asb_slv_csiphy clock gating control.
  [5] PCLK_APB2ASB_SLV_CDPHY_EN — pclk_apb2asb_slv_cdphy clock gating control.
  [4] PCLK_MIPI_DCPHY1_GRF_EN — pclk_mipi_dcphy1_grf clock gating control.
  [3] PCLK_MIPI_DCPHY1_EN — pclk_mipi_dcphy1 clock gating control.
0x814 GATE_CON05 — Internal clock gate and division register 5
  [all] fields
    1=DISABLE; 0=ENABLE
  [15] HCLK_CHANNEL_SECURE2CENTER_EN — hclk_channel_secure2center clock gating control.
  [14] HCLK_CHANNEL_SECURE2VO1USB_EN — hclk_channel_secure2vo1usb clock gating control.
  [n+9] CLK_MIPI_CAMERAOUT_M{n}_EN (n=0..4) — clk_mipi_camaraout_m{n} clock gating control.
  [8] ACLK_CHANNEL_SECURE2CENTER_EN — aclk_channel_secure2center clock gating control.
  [7] ACLK_CHANNEL_SECURE2VO1USB_EN — aclk_channel_secure2vo1usb clock gating control.
  [6] CLK_CIFOUT_OUT_EN — clk_cifout_out clock gating control.
  [5] REFCLKO25M_ETH1_OUT_EN — refclko25m_eth1_out clock gating control.
  [4] REFCLKO25M_ETH0_OUT_EN — refclko25m_eth0_out clock gating control.
  [3] MCLK_GMAC0_OUT_EN — mclk_gmac0_out clock gating control.
  [0] PCLK_CRU_EN — pclk_cru clock gating control.
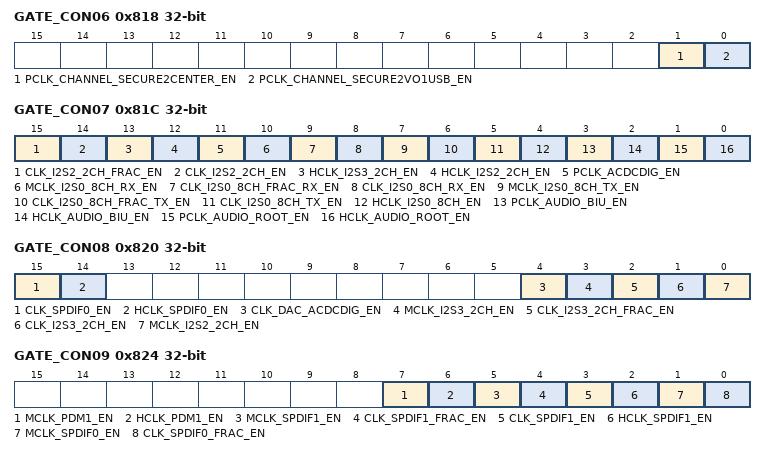
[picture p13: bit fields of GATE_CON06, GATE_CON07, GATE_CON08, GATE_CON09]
0x818 GATE_CON06 — Internal clock gate and division register 6
  [1] PCLK_CHANNEL_SECURE2CENTER_EN — pclk_channel_secure2center clock gating control.
    1=DISABLE; 0=ENABLE
  [0] PCLK_CHANNEL_SECURE2VO1USB_EN — pclk_channel_secure2vo1usb clock gating control.
    1=DISABLE; 0=ENABLE
0x81C GATE_CON07 — Internal clock gate and division register 7
  [all] fields
    1=DISABLE; 0=ENABLE
  [15] CLK_I2S2_2CH_FRAC_EN — clk_i2s2_2ch_frac clock gating control.
  [14] CLK_I2S2_2CH_EN — clk_i2s2_2ch_src clock gating control.
  [13] HCLK_I2S3_2CH_EN — hclk_i2s3_2ch clock gating control.
  [12] HCLK_I2S2_2CH_EN — hclk_i2s2_2ch clock gating control.
  [11] PCLK_ACDCDIG_EN — pclk_acdcdig clock gating control.
  [10] MCLK_I2S0_8CH_RX_EN — mclk_i2s0_8ch_rx clock gating control.
  [9] CLK_I2S0_8CH_FRAC_RX_EN — clk_i2s0_8ch_rx_frac clock gating control.
  [8] CLK_I2S0_8CH_RX_EN — clk_i2s0_8ch_rx_src clock gating control.
  [7] MCLK_I2S0_8CH_TX_EN — mclk_i2s0_8ch_tx clock gating control.
  [6] CLK_I2S0_8CH_FRAC_TX_EN — clk_i2s0_8ch_tx_frac clock gating control.
  [5] CLK_I2S0_8CH_TX_EN — clk_i2s0_8ch_tx_src clock gating control.
  [4] HCLK_I2S0_8CH_EN — hclk_i2s0_8ch clock gating control.
  [3] PCLK_AUDIO_BIU_EN — pclk_audio_biu clock gating control.
  [2] HCLK_AUDIO_BIU_EN — hclk_audio_biu clock gating control.
  [1] PCLK_AUDIO_ROOT_EN — pclk_audio_root clock gating control.
  [0] HCLK_AUDIO_ROOT_EN — hclk_audio_root clock gating control.
0x820 GATE_CON08 — Internal clock gate and division register 8
  [all] fields
    1=DISABLE; 0=ENABLE
  [15] CLK_SPDIF0_EN — clk_spdif0_src clock gating control.
  [14] HCLK_SPDIF0_EN — hclk_spdif0 clock gating control.
  [4] CLK_DAC_ACDCDIG_EN — clk_dac_acdcdig clock gating control.
  [3] MCLK_I2S3_2CH_EN — mclk_i2s3_2ch clock gating control.
  [2] CLK_I2S3_2CH_FRAC_EN — clk_i2s3_2ch_frac clock gating control.
  [1] CLK_I2S3_2CH_EN — clk_i2s3_2ch_src clock gating control.
  [0] MCLK_I2S2_2CH_EN — mclk_i2s2_2ch clock gating control.
0x824 GATE_CON09 — Internal clock gate and division register 9
  [all] fields
    1=DISABLE; 0=ENABLE
  [7] MCLK_PDM1_EN — mclk_pdm1 clock gating control.
  [6] HCLK_PDM1_EN — hclk_pdm1 clock gating control.
  [5] MCLK_SPDIF1_EN — mclk_spdif1 clock gating control.
  [4] CLK_SPDIF1_FRAC_EN — clk_spdif1_frac clock gating control.
  [3] CLK_SPDIF1_EN — clk_spdif1_src clock gating control.
  [2] HCLK_SPDIF1_EN — hclk_spdif1 clock gating control.
  [1] MCLK_SPDIF0_EN — mclk_spdif0 clock gating control.
  [0] CLK_SPDIF0_FRAC_EN — clk_spdif0_frac clock gating control.
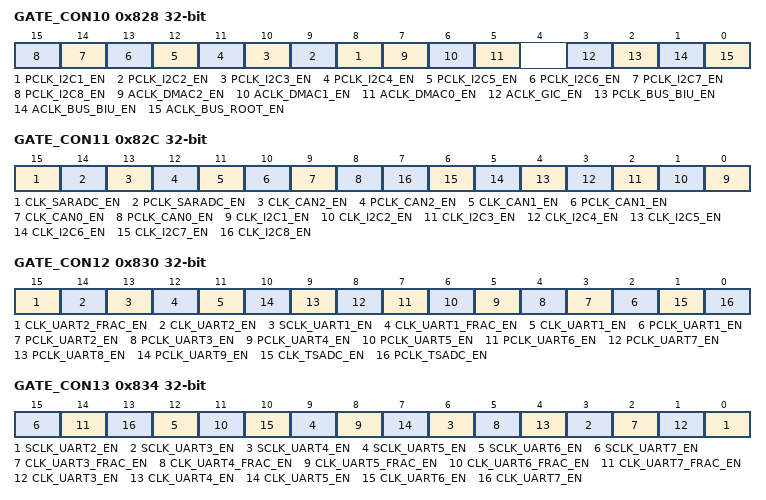
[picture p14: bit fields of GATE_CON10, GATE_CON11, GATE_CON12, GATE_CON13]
0x828 GATE_CON10 — Internal clock gate and division register 10
  [all] fields
    1=DISABLE; 0=ENABLE
  [n+7] PCLK_I2C{n}_EN (n=1..8) — pclk_i2c{n} clock gating control.
  [7] ACLK_DMAC2_EN — aclk_dmac2 clock gating control.
  [6] ACLK_DMAC1_EN — aclk_dmac1 clock gating control.
  [5] ACLK_DMAC0_EN — aclk_dmac0 clock gating control.
  [3] ACLK_GIC_EN — aclk_gic clock gating control.
  [2] PCLK_BUS_BIU_EN — pclk_bus_biu clock gating control.
  [1] ACLK_BUS_BIU_EN — aclk_bus_biu clock gating control.
  [0] ACLK_BUS_ROOT_EN — aclk_bus_root clock gating control.
0x82C GATE_CON11 — Internal clock gate and division register 11
  [all] fields
    1=DISABLE; 0=ENABLE
  [15] CLK_SARADC_EN — clk_saradc clock gating control.
  [14] PCLK_SARADC_EN — pclk_saradc clock gating control.
  [13] CLK_CAN2_EN — clk_can2 clock gating control.
  [12] PCLK_CAN2_EN — pclk_can2 clock gating control.
  [11] CLK_CAN1_EN — clk_can1 clock gating control.
  [10] PCLK_CAN1_EN — pclk_can1 clock gating control.
  [9] CLK_CAN0_EN — clk_can0 clock gating control.
  [8] PCLK_CAN0_EN — pclk_can0 clock gating control.
  [n-1] CLK_I2C{n}_EN (n=1..8) — clk_i2c{n} clock gating control.
0x830 GATE_CON12 — Internal clock gate and division register 12
  [all] fields
    1=DISABLE; 0=ENABLE
  [15] CLK_UART2_FRAC_EN — clk_uart2_frac clock gating control.
  [14] CLK_UART2_EN — clk_uart2_src clock gating control.
  [13] SCLK_UART1_EN — sclk_uart1 clock gating control.
  [12] CLK_UART1_FRAC_EN — clk_uart1_frac clock gating control.
  [11] CLK_UART1_EN — clk_uart1_src clock gating control.
  [n+1] PCLK_UART{n}_EN (n=1..9) — pclk_uart{n} clock gating control.
  [1] CLK_TSADC_EN — clk_tsadc clock gating control.
  [0] PCLK_TSADC_EN — pclk_tsadc clock gating control.
0x834 GATE_CON13 — Internal clock gate and division register 13
  [all] fields
    1=DISABLE; 0=ENABLE
  [3n-6] SCLK_UART{n}_EN (n=2..7) — sclk_uart{n} clock gating control.
  [3n-7] CLK_UART{n}_FRAC_EN (n=3..7) — clk_uart{n}_frac clock gating control.
  [3n-8] CLK_UART{n}_EN (n=3..7) — clk_uart{n}_src clock gating control.
0x838 GATE_CON14 — Internal clock gate and division register 14
  [all] fields
    1=DISABLE; 0=ENABLE
  [n+11] CLK_SPI{n}_EN (n=0..4) — clk_spi{n} clock gating control.
  [n+6] PCLK_SPI{n}_EN (n=0..4) — pclk_spi{n} clock gating control.
  [5] SCLK_UART9_EN — sclk_uart9 clock gating control.
  [4] CLK_UART9_FRAC_EN — clk_uart9_frac clock gating control.
  [3] CLK_UART9_EN — clk_uart9_src clock gating control.
  [2] SCLK_UART8_EN — sclk_uart8 clock gating control.
  [1] CLK_UART8_FRAC_EN — clk_uart8_frac clock gating control.
  [0] CLK_UART8_EN — clk_uart8_src clock gating control.
0x83C GATE_CON15 — Internal clock gate and division register 15
  [all] fields
    1=DISABLE; 0=ENABLE
  [15] CLK_BUSTIMER0_EN — clk_bustimer0 clock gating control.
  [14] CLK_BUSTIMER_ROOT_EN — clk_bus_timer_root clock gating control.
  [13] PCLK_BUSTIMER1_EN — pclk_bustimer1 clock gating control.
  [12] PCLK_BUSTIMER0_EN — pclk_bustimer0 clock gating control.
  [11] CLK_PWM3_CAPTURE_EN — clk_pwm3_capture clock gating control.
  [10] CLK_PWM3_EN — clk_pwm3 clock gating control.
  [9] PCLK_PWM3_EN — pclk_pwm3 clock gating control.
  [8] CLK_PWM2_CAPTURE_EN — clk_pwm2_capture clock gating control.
  [7] CLK_PWM2_EN — clk_pwm2 clock gating control.
  [6] PCLK_PWM2_EN — pclk_pwm2 clock gating control.
  [5] CLK_PWM1_CAPTURE_EN — clk_pwm1_capture clock gating control.
  [4] CLK_PWM1_EN — clk_pwm1 clock gating control.
  [3] PCLK_PWM1_EN — pclk_pwm1 clock gating control.
  [2] PCLK_SYS_GRF_EN — pclk_sys_grf clock gating control.
  [1] TCLK_WDT0_EN — tclk_wdt0 clock gating control.
  [0] PCLK_WDT0_EN — pclk_wdt0 clock gating control.
0x840 GATE_CON16 — Internal clock gate and division register 16
  [all] fields
    1=DISABLE; 0=ENABLE
  [15] DBCLK_GPIO1_EN — dbclk_gpio1 clock gating control.
  [14] PCLK_GPIO1_EN — pclk_gpio1 clock gating control.
  [13] PCLK_MAILBOX2_EN — pclk_mailbox2 clock gating control.
  [12] PCLK_MAILBOX1_EN — pclk_mailbox1 clock gating control.
  [11] PCLK_MAILBOX0_EN — pclk_mailbox0 clock gating control.
  [n-1] CLK_BUSTIMER{n}_EN (n=1..11) — clk_bustimer{n} clock gating control.
0x844 GATE_CON17 — Internal clock gate and division register 17
  [all] fields
    1=DISABLE; 0=ENABLE
  [15] PCLK_APB2ASB_MST_BOT_RIGHT_EN — pclk_apb2asb_mst_bot_right clock gating control.
  [14] PCLK_APB2ASB_MST_CDPHY_EN — pclk_apb2asb_mst_cdphy clock gating control.
  [13] PCLK_APB2ASB_MST_TOP_EN — pclk_apb2asb_mst_top clock gating control.
  [12] PCLK_DFT2APB_EN — pclk_dft2apb clock gating control.
  [11] ACLK_GICADB_GIC2CORE_BUS_EN — aclk_gicadb_gic2core_bus clock gating control.
  [9] PCLK_TOP_EN — pclk_top clock gating control.
  [8] DCLK_DECOM_EN — dclk_decom clock gating control.
  [7] PCLK_DECOM_EN — pclk_decom clock gating control.
  [6] ACLK_DECOM_EN — aclk_decom clock gating control.
  [5] DBCLK_GPIO4_EN — dbclk_gpio4 clock gating control.
  [4] PCLK_GPIO4_EN — pclk_gpio4 clock gating control.
  [3] DBCLK_GPIO3_EN — dbclk_gpio3 clock gating control.
  [2] PCLK_GPIO3_EN — pclk_gpio3 clock gating control.
  [1] DBCLK_GPIO2_EN — dbclk_gpio2 clock gating control.
  [0] PCLK_GPIO2_EN — pclk_gpio2 clock gating control.
0x848 GATE_CON18 — Internal clock gate and division register 18
  [all] fields
    1=DISABLE; 0=ENABLE
  [13] CLK_OTP_PHY_EN — clk_otp_phy_g clock gating control.
  [12] CLK_OTPC_AUTO_RD_EN — clk_otpc_auto_rd_g clock gating control.
  [11] CLK_OTPC_ARB_EN — clk_otpc_arb clock gating control.
  [10] CLK_OTPC_NS_EN — clk_otpc_ns clock gating control.
  [9] PCLK_OTPC_NS_EN — pclk_otpc_ns clock gating control.
  [6] ACLK_SPINLOCK_EN — aclk_spinlock clock gating control.
  [5] PCLK_APB2ASB_MST_EMMCIO_EN — pclk_apb2asb_mst_emmcio clock gating control.
  [4] PCLK_APB2ASB_MST_VCCIO6_EN — pclk_apb2asb_mst_vccio6 clock gating control.
  [3] PCLK_APB2ASB_MST_VCCIO3_5_EN — pclk_apb2asb_mst_vccio3_5 clock gating control.
  [2] PCLK_APB2ASB_MST_CSIPHY_EN — pclk_apb2asb_mst_csiphy clock gating control.
  [1] PCLK_APB2ASB_MST_IOC_RIGHT_EN — pclk_apb2asb_mst_ioc_right clock gating control.
  [0] PCLK_APB2ASB_MST_IOC_TOP_EN — pclk_apb2asb_mst_ioc_top clock gating control.
0x84C GATE_CON19 — Internal clock gate and division register 19
  [all] fields
    1=DISABLE; 0=ENABLE
  [5] PCLK_DDRCM0_INTMUX_EN — pclk_ddrcm0_intmux clock gating control.
  [4] PCLK_PMUCM0_INTMUX_EN — pclk_pmucm0_intmux clock gating control.
  [3] PCLK_PMU2_EN — pclk_pmu2 clock gating control.
  [2] CLK_BISRINTF_EN — clk_bisrintf clock gating control.
  [1] CLK_BISRINTF_PLLSRC_EN — clk_bisrintf_pllsrc clock gating control.
  [0] PCLK_BUSIOC_EN — pclk_busioc clock gating control.
0x850 GATE_CON20 — Internal clock gate and division register 20
  [all] fields
    1=DISABLE; 0=ENABLE
  [15] PCLK_DDR_STANDBY_CH1_EN — pclk_ddr_standby_ch1 clock gating control.
  [14] PCLK_DDR_MON_CH1_EN — pclk_ddr_mon_ch1 clock gating control.
  [13] PCLK_DDR_DFICTL_CH1_EN — pclk_ddr_dfictl_ch1 clock gating control.
  [12] ACLK_DDR_UPCTL_CH0_EN — aclk_ddr_upctl_ch0 clock gating control.
  [11] CLK_DDR_STANDBY_CH0_EN — clk_ddr_standby_ch0 clock gating control.
  [10] CLK_DDR_MON_CH0_EN — clk_ddr_mon_ch0 clock gating control.
  [9] CLK_DDR_DFICTL_CH0_EN — clk_ddr_dfictl_ch0 clock gating control.
  [8] CLK_DDR_UPCTL_CH0_EN — clk_ddr_upctl_ch0 clock gating control.
  [7] CLK_SBR_CH0_EN — clk_sbr_ch0 clock gating control.
  [6] CLK_DFI_CH0_EN — clk_dfi_ch0 clock gating control.
  [5] PCLK_DDR_GRF_CH01_EN — pclk_ddr_grf_ch01 clock gating control, both ddr ch0 and ddr ch1.
  [4] TMCLK_DDR_MON_CH0_EN — tmclk_ddr_mon_ch0 clock gating control.
  [3] PCLK_DDR_UPCTL_CH0_EN — pclk_ddr_upctl_ch0 clock gating control.
  [2] PCLK_DDR_STANDBY_CH0_EN — pclk_ddr_standby_ch0 clock gating control.
  [1] PCLK_DDR_MON_CH0_EN — pclk_ddr_mon_ch0 clock gating control.
  [0] PCLK_DDR_DFICTL_CH0_EN — pclk_ddr_dfictl_ch0 clock gating control.
